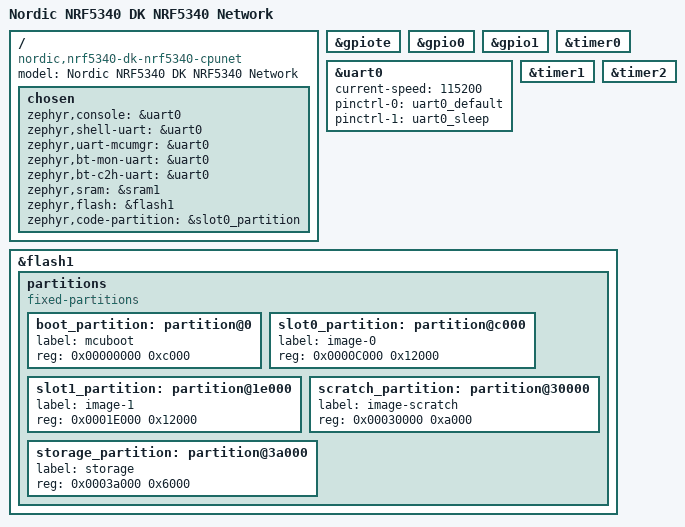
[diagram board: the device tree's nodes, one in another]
/*
 * Copyright (c) 2020 Nordic Semiconductor ASA
 *
 * SPDX-License-Identifier: Apache-2.0
 */

/dts-v1/;
#include <nordic/nrf5340_cpunet_qkaa.dtsi>
#include "nrf5340dk_nrf5340_cpunet-pinctrl.dtsi"

/ {
	model = "Nordic NRF5340 DK NRF5340 Network";
	compatible = "nordic,nrf5340-dk-nrf5340-cpunet";

	chosen {
		zephyr,console = &uart0;
		zephyr,shell-uart = &uart0;
		zephyr,uart-mcumgr = &uart0;
		zephyr,bt-mon-uart = &uart0;
		zephyr,bt-c2h-uart = &uart0;
		zephyr,sram = &sram1;
		zephyr,flash = &flash1;
		zephyr,code-partition = &slot0_partition;
	};

/*	leds {
		compatible = "gpio-leds";
		led0: led_0 {
			gpios = <&gpio1 4 GPIO_ACTIVE_LOW>;
			label = "Green LED 0";
		};
		led1: led_1 {
			gpios = <&gpio1 5 GPIO_ACTIVE_LOW>;
			label = "Green LED 1";
		};
		led2: led_2 {
			gpios = <&gpio0 19 GPIO_ACTIVE_LOW>;
			label = "Green LED 2";
		};
		led3: led_3 {
			gpios = <&gpio0 31 GPIO_ACTIVE_LOW>;
			label = "Green LED 3";
		};
	};*/

	/*buttons {
		compatible = "gpio-keys";
		button0: button_0 {
			gpios = <&gpio0 23 (GPIO_PULL_UP | GPIO_ACTIVE_LOW)>;
			label = "Push button 1";
		};
		button1: button_1 {
			gpios = <&gpio0 24 (GPIO_PULL_UP | GPIO_ACTIVE_LOW)>;
			label = "Push button 2";
		};
		button2: button_2 {
			gpios = <&gpio0 8 (GPIO_PULL_UP | GPIO_ACTIVE_LOW)>;
			label = "Push button 3";
		};
		button3: button_3 {
			gpios = <&gpio0 9 (GPIO_PULL_UP | GPIO_ACTIVE_LOW)>;
			label = "Push button 4";
		};
	};*/

	/*arduino_header: connector {
		compatible = "arduino-header-r3";
		#gpio-cells = <2>;
		gpio-map-mask = <0xffffffff 0xffffffc0>;
		gpio-map-pass-thru = <0 0x3f>;
		gpio-map = <0 0 &gpio0 4 0>,	
			   <1 0 &gpio0 5 0>,	
			   <2 0 &gpio0 6 0>,	
			   <3 0 &gpio0 7 0>,	
			   <4 0 &gpio0 25 0>,	
			   <5 0 &gpio0 26 0>,	
			   <6 0 &gpio1 0 0>,	
			   <7 0 &gpio1 1 0>,	
			   <8 0 &gpio1 4 0>,	
			   <9 0 &gpio1 5 0>,	
			   <10 0 &gpio1 6 0>,	
			   <11 0 &gpio1 7 0>,	
			   <12 0 &gpio1 8 0>,	
			   <13 0 &gpio1 9 0>,	
			   <14 0 &gpio1 10 0>,	
			   <15 0 &gpio1 11 0>,	
			   <16 0 &gpio1 12 0>,	
			   <17 0 &gpio1 13 0>,	
			   <18 0 &gpio1 14 0>,	
			   <19 0 &gpio1 15 0>,	
			   <20 0 &gpio1 2 0>,	
			   <21 0 &gpio1 3 0>;	
	};*/

	/* These aliases are provided for compatibility with samples */
	/*aliases {
		led0 = &led0;
		led1 = &led1;
		led2 = &led2;
		//led3 = &led3;
		sw0 = &button0;
		sw1 = &button1;
		sw2 = &button2;
		sw3 = &button3;
		bootloader-led0 = &led0;
	};*/
};

&gpiote {
	status = "okay";
};

&gpio0 {
	status = "okay";
};

&gpio1 {
	status = "okay";
};

&uart0 {
	status = "okay";
	current-speed = <115200>;
	pinctrl-0 = <&uart0_default>;
	pinctrl-1 = <&uart0_sleep>;
	pinctrl-names = "default", "sleep";
};

/*arduino_serial: &uart0{};

arduino_i2c: &i2c0 {
	compatible = "nordic,nrf-twim";
	
	
	pinctrl-0 = <&i2c0_default>;
	pinctrl-1 = <&i2c0_sleep>;
	pinctrl-names = "default", "sleep";
};

arduino_spi: &spi0 {
	compatible = "nordic,nrf-spim";
	
	
	cs-gpios = <&arduino_header 16 GPIO_ACTIVE_LOW>; 
	
	pinctrl-0 = <&spi0_default>;
	pinctrl-1 = <&spi0_sleep>;
	pinctrl-names = "default", "sleep";
};*/

&timer0 {
	status = "okay";
};

&timer1 {
	status = "okay";
};

&timer2 {
	status = "okay";
};

&flash1 {

	partitions {
		compatible = "fixed-partitions";
		#address-cells = <1>;
		#size-cells = <1>;

		boot_partition: partition@0 {
			label = "mcuboot";
			reg = <0x00000000 0xc000>;
		};
		slot0_partition: partition@c000 {
			label = "image-0";
			reg = <0x0000C000 0x12000>;
		};
		slot1_partition: partition@1e000 {
			label = "image-1";
			reg = <0x0001E000 0x12000>;
		};
		scratch_partition: partition@30000 {
			label = "image-scratch";
			reg = <0x00030000 0xa000>;
		};
		storage_partition: partition@3a000 {
			label = "storage";
			reg = <0x0003a000 0x6000>;
		};
	};
};

/* Include shared RAM configuration file */
#include "nrf5340_shared_sram_planning_conf.dts"
